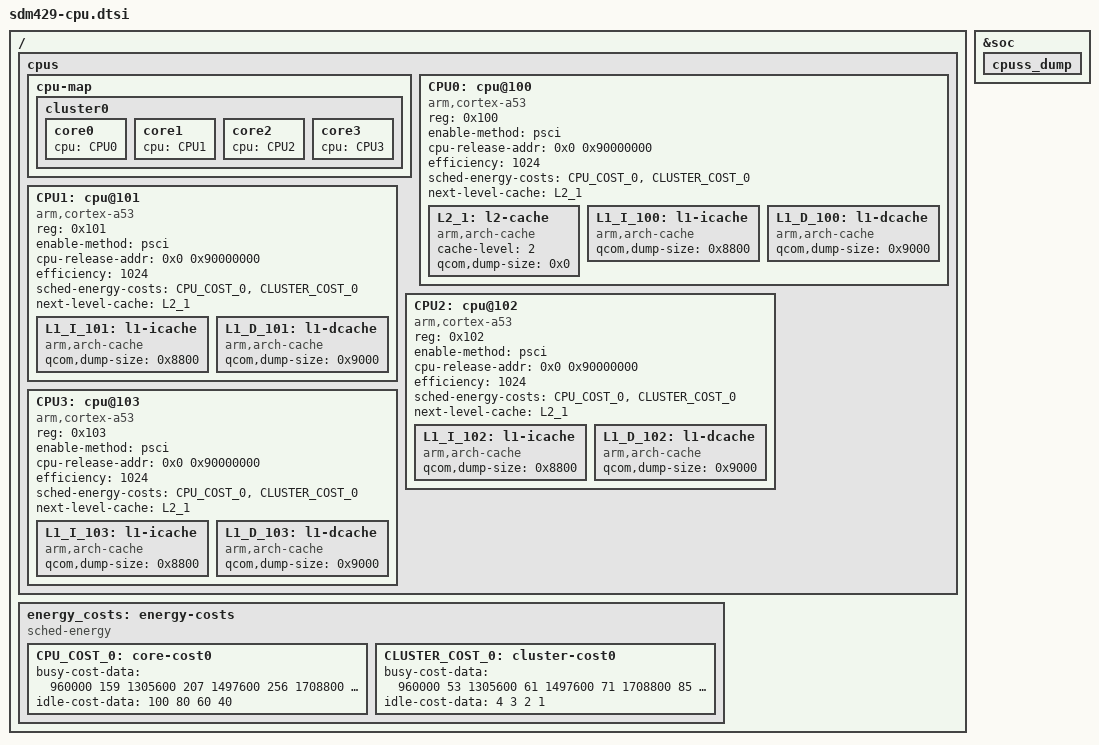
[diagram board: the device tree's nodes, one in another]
/*
 * Copyright (c) 2018, The Linux Foundation. All rights reserved.
 *
 * This program is free software; you can redistribute it and/or modify
 * it under the terms of the GNU General Public License version 2 and
 * only version 2 as published by the Free Software Foundation.
 *
 * This program is distributed in the hope that it will be useful,
 * but WITHOUT ANY WARRANTY; without even the implied warranty of
 * MERCHANTABILITY or FITNESS FOR A PARTICULAR PURPOSE.  See the
 * GNU General Public License for more details.
 */

/ {
	/delete-node/ cpus;
	/delete-node/ energy-costs;

	cpus {
		#address-cells = <1>;
		#size-cells = <0>;
		cpu-map {
			cluster0 {
				core0 {
					cpu = <&CPU0>;
				};
				core1 {
					cpu = <&CPU1>;
				};
				core2 {
					cpu = <&CPU2>;
				};
				core3 {
					cpu = <&CPU3>;
				};
			};
		};

		CPU0: cpu@100 {
			device_type = "cpu";
			compatible = "arm,cortex-a53";
			reg = <0x100>;
			enable-method = "psci";
			cpu-release-addr = <0x0 0x90000000>;
			efficiency = <1024>;
			sched-energy-costs = <&CPU_COST_0 &CLUSTER_COST_0>;
			next-level-cache = <&L2_1>;
			#cooling-cells = <2>;
			L2_1: l2-cache {
			      compatible = "arm,arch-cache";
			      cache-level = <2>;
			      /* A53 L2 dump not supported */
			      qcom,dump-size = <0x0>;
			};
			L1_I_100: l1-icache {
				compatible = "arm,arch-cache";
				qcom,dump-size = <0x8800>;
			};
			L1_D_100: l1-dcache {
				compatible = "arm,arch-cache";
				qcom,dump-size = <0x9000>;
			};
		};

		CPU1: cpu@101 {
			device_type = "cpu";
			compatible = "arm,cortex-a53";
			reg = <0x101>;
			enable-method = "psci";
			cpu-release-addr = <0x0 0x90000000>;
			efficiency = <1024>;
			sched-energy-costs = <&CPU_COST_0 &CLUSTER_COST_0>;
			next-level-cache = <&L2_1>;
			#cooling-cells = <2>;
			L1_I_101: l1-icache {
				compatible = "arm,arch-cache";
				qcom,dump-size = <0x8800>;
			};
			L1_D_101: l1-dcache {
				compatible = "arm,arch-cache";
				qcom,dump-size = <0x9000>;
			};
		};

		CPU2: cpu@102 {
			device_type = "cpu";
			compatible = "arm,cortex-a53";
			reg = <0x102>;
			enable-method = "psci";
			cpu-release-addr = <0x0 0x90000000>;
			efficiency = <1024>;
			sched-energy-costs = <&CPU_COST_0 &CLUSTER_COST_0>;
			next-level-cache = <&L2_1>;
			#cooling-cells = <2>;
			L1_I_102: l1-icache {
				compatible = "arm,arch-cache";
				qcom,dump-size = <0x8800>;
			};
			L1_D_102: l1-dcache {
				compatible = "arm,arch-cache";
				qcom,dump-size = <0x9000>;
			};
		};

		CPU3: cpu@103 {
			device_type = "cpu";
			compatible = "arm,cortex-a53";
			reg = <0x103>;
			enable-method = "psci";
			cpu-release-addr = <0x0 0x90000000>;
			efficiency = <1024>;
			sched-energy-costs = <&CPU_COST_0 &CLUSTER_COST_0>;
			next-level-cache = <&L2_1>;
			#cooling-cells = <2>;
			L1_I_103: l1-icache {
				compatible = "arm,arch-cache";
				qcom,dump-size = <0x8800>;
			};
			L1_D_103: l1-dcache {
				compatible = "arm,arch-cache";
				qcom,dump-size = <0x9000>;
			};
		};

	};

	energy_costs: energy-costs {
		compatible = "sched-energy";

		CPU_COST_0: core-cost0 {
			busy-cost-data = <
				 960000	159
				1305600	207
				1497600	256
				1708800	327
				1804800	343
				1958400	445
				2016000	470
			>;
			idle-cost-data = <
				100 80 60 40
			>;
		};
		CLUSTER_COST_0: cluster-cost0 {
			busy-cost-data = <
				 960000	53
				1305600	61
				1497600	71
				1708800	85
				1804800	88
				1958400	110
				2016000	120
			>;
			idle-cost-data = <
				4 3 2 1
			>;
		};
	};
};

&soc {
	cpuss_dump {
		/delete-node/ qcom,l2_dump0;
		/delete-node/ qcom,l1_i_cache0;
		/delete-node/ qcom,l1_i_cache1;
		/delete-node/ qcom,l1_i_cache2;
		/delete-node/ qcom,l1_i_cache3;
		/delete-node/ qcom,l1_d_cache0;
		/delete-node/ qcom,l1_d_cache1;
		/delete-node/ qcom,l1_d_cache2;
		/delete-node/ qcom,l1_d_cache3;
	};
};
